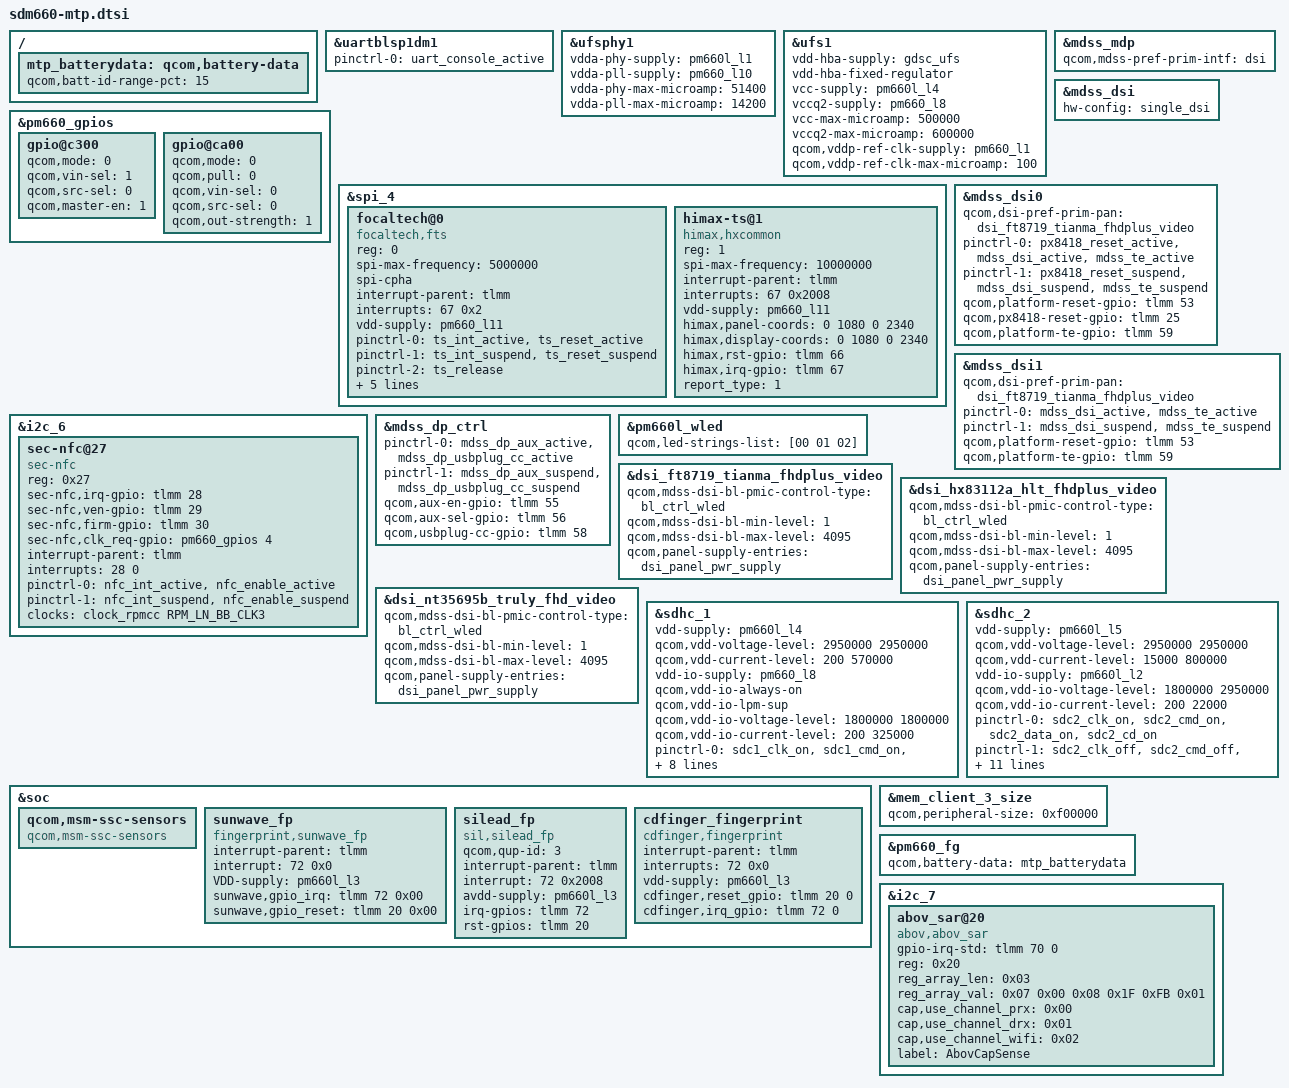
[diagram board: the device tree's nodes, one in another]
/* Copyright (c) 2016-2018, The Linux Foundation. All rights reserved.
 *
 * This program is free software; you can redistribute it and/or modify
 * it under the terms of the GNU General Public License version 2 and
 * only version 2 as published by the Free Software Foundation.
 *
 * This program is distributed in the hope that it will be useful,
 * but WITHOUT ANY WARRANTY; without even the implied warranty of
 * MERCHANTABILITY or FITNESS FOR A PARTICULAR PURPOSE.  See the
 * GNU General Public License for more details.
 */

#include "sdm660-pinctrl.dtsi"
#include "sdm660-camera-sensor-mtp.dtsi"
/ {
	mtp_batterydata: qcom,battery-data {
		qcom,batt-id-range-pct = <15>;
		#include "fg-gen3-batterydata-m690-Veken-3500mAH.dtsi"
		#include "fg-gen3-batterydata-m690-ATL-3500mAH.dtsi"
	};
};

&uartblsp1dm1 {
	status = "ok";
	pinctrl-names = "default";
	pinctrl-0 = <&uart_console_active>;
};

&ufsphy1 {
	vdda-phy-supply = <&pm660l_l1>;
	vdda-pll-supply = <&pm660_l10>;
	vdda-phy-max-microamp = <51400>;
	vdda-pll-max-microamp = <14200>;
	status = "ok";
};

&ufs1 {
	vdd-hba-supply = <&gdsc_ufs>;
	vdd-hba-fixed-regulator;
	vcc-supply = <&pm660l_l4>;
	vccq2-supply = <&pm660_l8>;
	vcc-max-microamp = <500000>;
	vccq2-max-microamp = <600000>;
	qcom,vddp-ref-clk-supply = <&pm660_l1>;
	qcom,vddp-ref-clk-max-microamp = <100>;

	status = "ok";
};

&pm660_gpios {
	/* GPIO 4 (NFC_CLK_REQ) */
	gpio@c300 {
		qcom,mode = <0>;
		qcom,vin-sel = <1>;
		qcom,src-sel = <0>;
		qcom,master-en = <1>;
		status = "okay";
	};

	/* GPIO 11 for Home Key */
	gpio@ca00 {
		status = "okay";
		qcom,mode = <0>;
		qcom,pull = <0>;
		qcom,vin-sel = <0>;
		qcom,src-sel = <0>;
		qcom,out-strength = <1>;
	};
};

&spi_4 { 
        status = "okay";
        focaltech@0{
		compatible = "focaltech,fts";
                #address-cells = <1>;
                #size-cells = <1>;
                reg = <0>; // Chip select 0 
                spi-max-frequency = <5000000>;
                spi-cpha;
		interrupt-parent = <&tlmm>;
		interrupts = <67 0x2>;
		vdd-supply = <&pm660_l11>;
		// pins used by touchscreen 
                pinctrl-names = "pmx_ts_active","pmx_ts_suspend","pmx_ts_release";
                pinctrl-0 = <&ts_int_active &ts_reset_active>;
                pinctrl-1 = <&ts_int_suspend &ts_reset_suspend>;
                pinctrl-2 = <&ts_release>;
		focaltech,name = "fts_ts";
		focaltech,reset-gpio = <&tlmm 66 0x01>;
		focaltech,irq-gpio = <&tlmm 67 0x02>;
		focaltech,display-coords = <0 0 1080 2340>;
		focaltech,max-touch-number = <10>;
	};

        himax-ts@1{
		compatible = "himax,hxcommon";
                #address-cells = <1>;
                #size-cells = <1>;
                reg = <1>; // Chip select 1 
                spi-max-frequency = <10000000>; //modify by shenwenbin for wakeup slowly 20190610
                //spi-cpol;
		//spi-cpha;
		interrupt-parent = <&tlmm>;
		interrupts = <67 0x2008>;
		vdd-supply = <&pm660_l11>;
                himax,panel-coords      = <0 1080 0 2340>;
                himax,display-coords    = <0 1080 0 2340>;
		himax,rst-gpio          = <&tlmm 66 0x00>;
		himax,irq-gpio          = <&tlmm 67 0x2008>;
                report_type             = <1>;
	};
};

&i2c_6 { /* BLSP1 QUP6 (NFC) */
	status = "okay";
	sec-nfc@27 {
		compatible = "sec-nfc";
		reg = <0x27>;
		sec-nfc,irq-gpio = <&tlmm 28 0x00>;
		sec-nfc,ven-gpio = <&tlmm 29 0x00>;
		sec-nfc,firm-gpio = <&tlmm 30 0x00>;
		sec-nfc,clk_req-gpio = <&pm660_gpios 4 0x00>;
		interrupt-parent = <&tlmm>;
		interrupts = <28 0>;
		interrupt-names = "nfc_irq";
		pinctrl-names = "nfc_active", "nfc_suspend";
		pinctrl-0 = <&nfc_int_active &nfc_enable_active>;
		pinctrl-1 = <&nfc_int_suspend &nfc_enable_suspend>;
		clocks = <&clock_rpmcc RPM_LN_BB_CLK3>;
		clock-names = "OSC_NFC";
	};
};

&mdss_mdp {
	qcom,mdss-pref-prim-intf = "dsi";
};

&mdss_dsi {
	hw-config = "single_dsi";
};

&mdss_dsi0 {
	qcom,dsi-pref-prim-pan = <&dsi_ft8719_tianma_fhdplus_video>;
	pinctrl-names = "mdss_default", "mdss_sleep";
	pinctrl-0 = <&px8418_reset_active &mdss_dsi_active &mdss_te_active>;
	pinctrl-1 = <&px8418_reset_suspend &mdss_dsi_suspend &mdss_te_suspend>;
	qcom,platform-reset-gpio = <&tlmm 53 0>;
	qcom,px8418-reset-gpio = <&tlmm 25 0>;
	qcom,platform-te-gpio = <&tlmm 59 0>;
};

&mdss_dsi1 {
	qcom,dsi-pref-prim-pan = <&dsi_ft8719_tianma_fhdplus_video>;
	pinctrl-names = "mdss_default", "mdss_sleep";
	pinctrl-0 = <&mdss_dsi_active &mdss_te_active>;
	pinctrl-1 = <&mdss_dsi_suspend &mdss_te_suspend>;
	qcom,platform-reset-gpio = <&tlmm 53 0>;
	qcom,platform-te-gpio = <&tlmm 59 0>;
};

&mdss_dp_ctrl {
	pinctrl-names = "mdss_dp_active", "mdss_dp_sleep";
	pinctrl-0 = <&mdss_dp_aux_active &mdss_dp_usbplug_cc_active>;
	pinctrl-1 = <&mdss_dp_aux_suspend &mdss_dp_usbplug_cc_suspend>;
	qcom,aux-en-gpio = <&tlmm 55 0>;
	qcom,aux-sel-gpio = <&tlmm 56 0>;
	qcom,usbplug-cc-gpio = <&tlmm 58 0>;
};

&pm660l_wled {
	qcom,led-strings-list = [00 01 02];
};

&dsi_ft8719_tianma_fhdplus_video {
        qcom,mdss-dsi-bl-pmic-control-type = "bl_ctrl_wled";
        qcom,mdss-dsi-bl-min-level = <1>;
        qcom,mdss-dsi-bl-max-level = <4095>;
        qcom,panel-supply-entries = <&dsi_panel_pwr_supply>;
};

&dsi_hx83112a_hlt_fhdplus_video {
        qcom,mdss-dsi-bl-pmic-control-type = "bl_ctrl_wled";
        qcom,mdss-dsi-bl-min-level = <1>;
        qcom,mdss-dsi-bl-max-level = <4095>;
        qcom,panel-supply-entries = <&dsi_panel_pwr_supply>;
};
/*modify by shenwenbin for M690 display 20190312 end*/
/*
&dsi_dual_nt35597_truly_video {
	qcom,mdss-dsi-bl-pmic-control-type = "bl_ctrl_wled";
	qcom,mdss-dsi-bl-min-level = <1>;
	qcom,mdss-dsi-bl-max-level = <4095>;
	qcom,mdss-dsi-mode-sel-gpio-state = "dual_port";
	qcom,panel-supply-entries = <&dsi_panel_pwr_supply>;
};

&dsi_dual_nt35597_truly_cmd {
	qcom,mdss-dsi-bl-pmic-control-type = "bl_ctrl_wled";
	qcom,mdss-dsi-bl-min-level = <1>;
	qcom,mdss-dsi-bl-max-level = <4095>;
	qcom,mdss-dsi-mode-sel-gpio-state = "dual_port";
	qcom,panel-supply-entries = <&dsi_panel_pwr_supply>;
};

&dsi_dual_sharp_video {
	qcom,mdss-dsi-bl-pmic-control-type = "bl_ctrl_wled";
	qcom,mdss-dsi-bl-min-level = <1>;
	qcom,mdss-dsi-bl-max-level = <4095>;
	qcom,panel-supply-entries = <&dsi_panel_pwr_supply>;
};

&dsi_nt35597_truly_dsc_video {
	qcom,mdss-dsi-bl-pmic-control-type = "bl_ctrl_wled";
	qcom,mdss-dsi-bl-min-level = <1>;
	qcom,mdss-dsi-bl-max-level = <4095>;
	qcom,panel-supply-entries = <&dsi_panel_pwr_supply>;
};

&dsi_nt35597_truly_dsc_cmd {
	qcom,mdss-dsi-bl-pmic-control-type = "bl_ctrl_wled";
	qcom,mdss-dsi-bl-min-level = <1>;
	qcom,mdss-dsi-bl-max-level = <4095>;
	qcom,panel-supply-entries = <&dsi_panel_pwr_supply>;
};
*/
&dsi_nt35695b_truly_fhd_video {
	qcom,mdss-dsi-bl-pmic-control-type = "bl_ctrl_wled";
	qcom,mdss-dsi-bl-min-level = <1>;
	qcom,mdss-dsi-bl-max-level = <4095>;
	qcom,panel-supply-entries = <&dsi_panel_pwr_supply>;
};
/*
&dsi_nt35695b_truly_fhd_cmd {
	qcom,mdss-dsi-bl-pmic-control-type = "bl_ctrl_wled";
	qcom,mdss-dsi-bl-min-level = <1>;
	qcom,mdss-dsi-bl-max-level = <4095>;
	qcom,panel-supply-entries = <&dsi_panel_pwr_supply>;
};

&dsi_rm67195_amoled_fhd_cmd {
	qcom,panel-supply-entries = <&dsi_panel_pwr_supply_labibb_amoled>;
};

&dsi_lgd_incell_sw49106_fhd_video {
	qcom,mdss-dsi-bl-pmic-control-type = "bl_ctrl_wled";
	qcom,mdss-dsi-bl-min-level = <1>;
	qcom,mdss-dsi-bl-max-level = <4095>;
	qcom,panel-supply-entries = <&dsi_panel_pwr_supply>;
};
*/

&sdhc_1 {
	/* device core power supply */
	vdd-supply = <&pm660l_l4>;
	qcom,vdd-voltage-level = <2950000 2950000>;
	qcom,vdd-current-level = <200 570000>;

	/* device communication power supply */
	vdd-io-supply = <&pm660_l8>;
	qcom,vdd-io-always-on;
	qcom,vdd-io-lpm-sup;
	qcom,vdd-io-voltage-level = <1800000 1800000>;
	qcom,vdd-io-current-level = <200 325000>;

	pinctrl-names = "active", "sleep";
	pinctrl-0 = <&sdc1_clk_on &sdc1_cmd_on &sdc1_data_on &sdc1_rclk_on>;
	pinctrl-1 = <&sdc1_clk_off &sdc1_cmd_off &sdc1_data_off &sdc1_rclk_off>;

	qcom,clk-rates = <400000 20000000 25000000 50000000 100000000 192000000
								384000000>;

	qcom,nonremovable;
	qcom,bus-speed-mode = "HS400_1p8v", "HS200_1p8v", "DDR_1p8v";

	status = "ok";
};

&sdhc_2 {
	/* device core power supply */
	vdd-supply = <&pm660l_l5>;
	qcom,vdd-voltage-level = <2950000 2950000>;
	qcom,vdd-current-level = <15000 800000>;

	/* device communication power supply */
	vdd-io-supply = <&pm660l_l2>;
	qcom,vdd-io-voltage-level = <1800000 2950000>;
	qcom,vdd-io-current-level = <200 22000>;

	pinctrl-names = "active", "sleep";
	pinctrl-0 = <&sdc2_clk_on &sdc2_cmd_on &sdc2_data_on &sdc2_cd_on>;
	pinctrl-1 = <&sdc2_clk_off &sdc2_cmd_off &sdc2_data_off &sdc2_cd_off>;

	#address-cells = <0>;
	interrupt-parent = <&sdhc_2>;
	interrupts = <0 1 2>;
	#interrupt-cells = <1>;
	interrupt-map-mask = <0xffffffff>;
	interrupt-map = <0 &intc 0 0 125 0
			1 &intc 0 0 221 0
			2 &tlmm 54 0>;
	interrupt-names = "hc_irq", "pwr_irq", "status_irq";
	cd-gpios = <&tlmm 54 0x0>;

	qcom,clk-rates = <400000 20000000 25000000 50000000 100000000
								200000000>;
	qcom,bus-speed-mode = "SDR12", "SDR25", "SDR50", "DDR50", "SDR104";

	status = "ok";
};

&soc {
	qcom,msm-ssc-sensors {
		compatible = "qcom,msm-ssc-sensors";
	};
	/* modify by zhoudan for fingerprint 20190311 begin */
	sunwave_fp {
		compatible = "fingerprint,sunwave_fp";
		interrupt-parent = <&tlmm>;
		interrupt = <72 0x0>;
		VDD-supply = <&pm660l_l3>;
		sunwave,gpio_irq = <&tlmm 72 0x00>;
		sunwave,gpio_reset = <&tlmm 20 0x00>;
		status = "ok";
	};
	silead_fp {
		compatible = "sil,silead_fp";
		qcom,qup-id=<3>;
		interrupt-parent = <&tlmm>;
		interrupt = <72 0x2008>;
		avdd-supply = <&pm660l_l3>;
		irq-gpios = <&tlmm 72 0x00>;
		rst-gpios = <&tlmm 20 0x00>;
		status = "ok";
	};
	cdfinger_fingerprint {
		compatible = "cdfinger,fingerprint";
		interrupt-parent = <&tlmm>;
		interrupts = <72 0x0>;
		vdd-supply = <&pm660l_l3>;
		cdfinger,reset_gpio = <&tlmm 20 0>;
		cdfinger,irq_gpio = <&tlmm 72 0>;
	};
	/* modify by zhoudan for fingerprint 20190311 end */
};

&mem_client_3_size {
	qcom,peripheral-size = <0xf00000>;
};

&pm660_fg {
	qcom,battery-data = <&mtp_batterydata>;
};

/*M690 donnot support parallel charging delete by wangyibo at 20190315*/
/*
&i2c_2 {
	status = "ok";
	smb1351-charger@1d {
		compatible = "qcom,smb1351-charger";
		reg = <0x1d>;
		qcom,parallel-charger;
		qcom,float-voltage-mv = <4400>;
		qcom,recharge-mv = <100>;
		qcom,parallel-en-pin-polarity = <1>;
	};
};
*/


//xiaopei add sar sensor begin 
&i2c_7 {
	status =  "okay";
	abov_sar@20 {				
				compatible = "abov,abov_sar";
				//gpio-irq = <70>;                  
				gpio-irq-std =<&tlmm 70 0>;
				reg = <0x20>;
				reg_array_len = <0x03>;
				reg_array_val = <0x07 0x00 0x08 0x1F 0xFB 0x01>;
				cap,use_channel_prx = <0x00>;
				cap,use_channel_drx = <0x01>;
				cap,use_channel_wifi = <0x02>;
				label = "AbovCapSense";
	           };
};
//xiaopei add sar sensor End
